# E203 register map
Vendor: Sipeed; Series: HBird Lichee tang
E203 CPU Coreplex, high-performance, 32-bit RV32IMAC core
CPU: E203, little endian
Registers are 32-bit, read-write, reset 0x0 unless marked. A register's access mark holds for its fields unless they carry their own. Offsets are from the block's base; lines under a group give offsets from that group; [hi:lo] are bit positions; {n}, {i} and the like mark numbered series; 'fields as' and 'values as' point back to an identical list; <NAME> marks a mode.

## Memory map
0x02000000 CLINT size 0x10000 — Core Local Interruptor.
0x0C000000 PLIC size 0x200008 — Platform-Level Interrupt Controller.
0x10000000 WDT size 0x40 — Watchdog Timer.
0x10000040 RTC size 0x30 — Real-Time Clock.
0x10000070 AON size 0x10 — AON Clock Configuration.
0x10000080 BACKUP size 0x80 — Backup Registers.
0x10000100 PMU size 0x50 — Power Management Unit.
0x10012000 GPIO0 size 0x1000 — General purpose input/output controller.
0x10013000 UART0 size 0x1000 — Universal Asynchronous Receiver/Transmitter.
0x10014000 QSPI0 size 0x1000 — Serial Peripheral Interface.
0x10015000 PWM0 size 0x1000 — Pulse-Width Modulation.
0x10023000 UART1 size 0x1000 — Universal Asynchronous Receiver/Transmitter.
0x10024000 QSPI1 size 0x1000 — Serial Peripheral Interface.
0x10025000 PWM1 size 0x1000
0x10034000 QSPI2 size 0x1000 — Serial Peripheral Interface.
0x10035000 PWM2 size 0x1000

## Interrupts
1 Watchdog_IRQ (WDT)
2 RTC_IRQ (RTC)
3 UART0_IRQ (UART0)
4 UART1_IRQ (UART1)
5 QSPI0_IRQ (QSPI0)
6 QSPI1_IRQ (QSPI1)
7 QSPI2_IRQ (QSPI2)
{n+8} GPIO_{n}_IRQ (GPIO0) (n=0..12)
21 GPIO_12_IRQ (GPIO0)
22 GPIO_14_IRQ (GPIO0)
23 GPIO_14_IRQ (GPIO0)
{n+8} GPIO_{n}_IRQ (GPIO0) (n=16..28)
37 GPIO_28_IRQ (GPIO0)
38 GPIO_30_IRQ (GPIO0)
39 GPIO_31_IRQ (GPIO0)
40 PWMO_CMP0_IRQ (PWM0)
41 PWMO_CMP1_IRQ (PWM0)
42 PWMO_CMP2_IRQ (PWM0)
43 PWMO_CMP3_IRQ (PWM0)
44 PWM1_CMP0_IRQ (PWM1)
45 PWM1_CMP1_IRQ (PWM1)
46 PWM1_CMP2_IRQ (PWM1)
47 PWM1_CMP3_IRQ (PWM1)
48 PWM2_CMP0_IRQ (PWM2)
49 PWM2_CMP1_IRQ (PWM2)
50 PWM2_CMP2_IRQ (PWM2)
51 PWM2_CMP3_IRQ (PWM2)

## PLIC — Platform-Level Interrupt Controller.
Base 0x0C000000
{0x0+4i} PRIORITY[{i}] (i=0..51) — PLIC Interrupt Priority Register.
  [2:0] PRIORITY
0x1000 PENDING_1 — PLIC Interrupt Pending Register 1.
0x1004 PENDING_2 — PLIC Interrupt Pending Register 2.
0x2000 ENABLE_1 — PLIC Interrupt Enable Register 1.
0x2004 ENABLE_2 — PLIC Interrupt Enable Register 2.
0x200000 THRESHOLD — PLIC Interrupt Priority Threshold Register.
  [2:0] THRESHOLD
0x200004 CLAIM — PLIC Claim/Complete Register.

## CLINT — Core Local Interruptor.
Base 0x02000000
0x00 MSIP — Machine Software Interrupt Pending Register.
0x4000 MTIMECMP_LO — Machine Timer Compare Register Low.
0x4004 MTIMECMP_HI — Machine Timer Compare Register High.
0xBFF8 MTIME_LO — Machine Timer Register Low.
0xBFFC MTIME_HI — Machine Timer Register High.

## GPIO0 — General purpose input/output controller.
Base 0x10012000
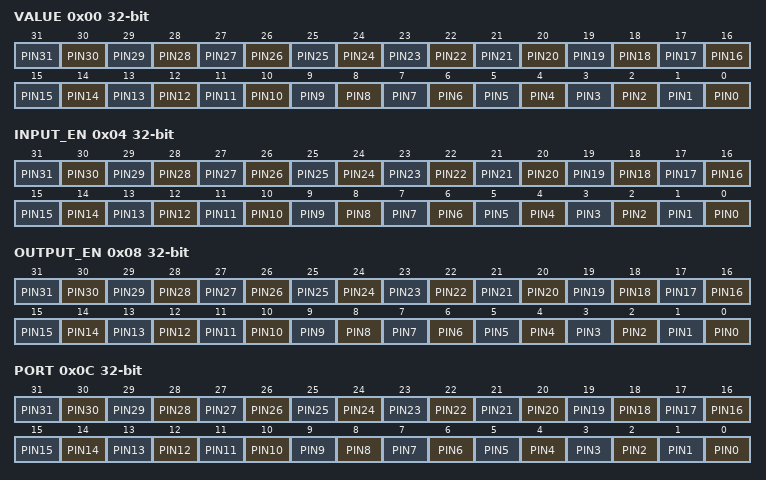
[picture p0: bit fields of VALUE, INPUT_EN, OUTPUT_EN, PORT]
0x00 VALUE — Pin value.
  [n] PIN{n} (n=0..31)
0x04 INPUT_EN — Pin input enable.
  [n] PIN{n} (n=0..31)
0x08 OUTPUT_EN — Pin output enable.
  [n] PIN{n} (n=0..31)
0x0C PORT — Output port value.
  [n] PIN{n} (n=0..31)
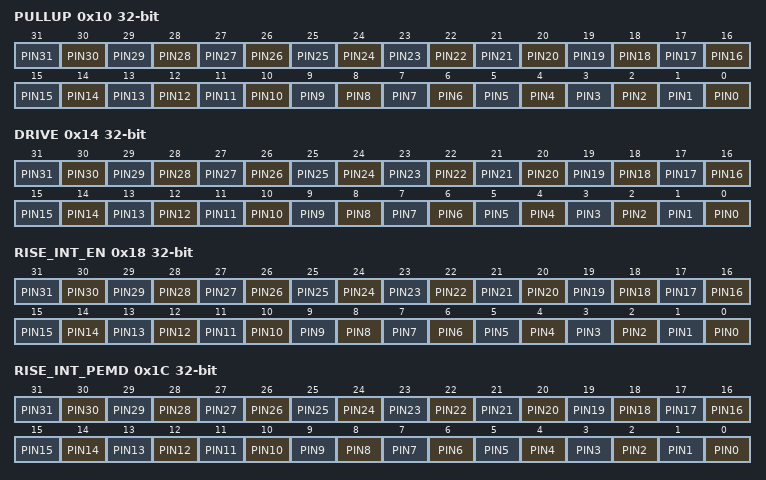
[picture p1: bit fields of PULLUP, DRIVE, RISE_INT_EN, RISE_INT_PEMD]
0x10 PULLUP — Internal Pull-Up enable.
  [n] PIN{n} (n=0..31)
0x14 DRIVE — Drive Strength.
  [n] PIN{n} (n=0..31)
0x18 RISE_INT_EN — Rise interrupt enable.
  [n] PIN{n} (n=0..31)
0x1C RISE_INT_PEMD — Rise interrupt pending.
  [n] PIN{n} (n=0..31)
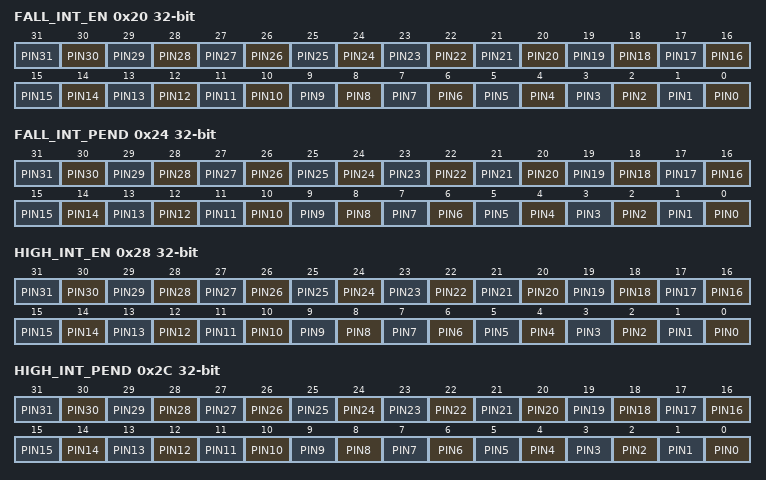
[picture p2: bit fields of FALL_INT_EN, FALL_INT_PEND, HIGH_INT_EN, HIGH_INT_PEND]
0x20 FALL_INT_EN — Fall interrupt enable.
  [n] PIN{n} (n=0..31)
0x24 FALL_INT_PEND — Fall interrupt pending.
  [n] PIN{n} (n=0..31)
0x28 HIGH_INT_EN — High interrupt enable.
  [n] PIN{n} (n=0..31)
0x2C HIGH_INT_PEND — High interrupt pending.
  [n] PIN{n} (n=0..31)
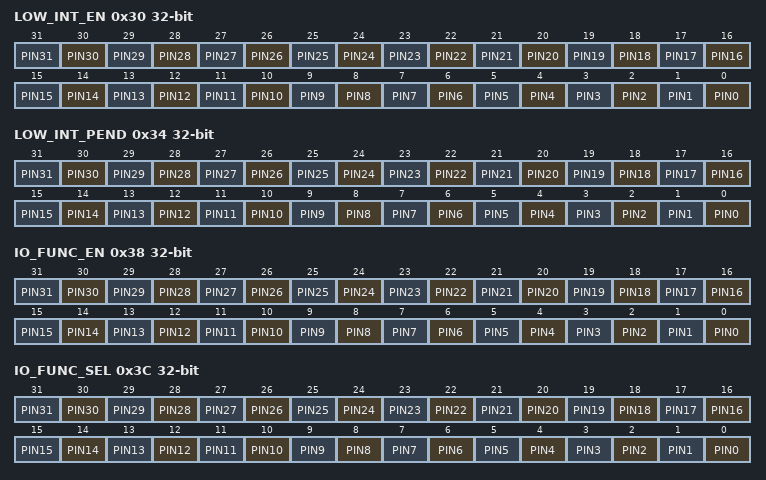
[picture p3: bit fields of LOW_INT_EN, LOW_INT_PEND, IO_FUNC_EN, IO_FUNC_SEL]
0x30 LOW_INT_EN — Low interrupt enable.
  [n] PIN{n} (n=0..31)
0x34 LOW_INT_PEND — Low interrupt pending.
  [n] PIN{n} (n=0..31)
0x38 IO_FUNC_EN — HW I/O function enable.
  [n] PIN{n} (n=0..31)
0x3C IO_FUNC_SEL — HW I/O function select.
  [n] PIN{n} (n=0..31)
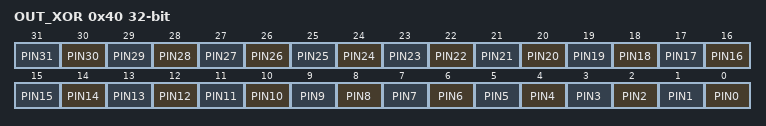
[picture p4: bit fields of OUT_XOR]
0x40 OUT_XOR — Output XOR (invert).
  [n] PIN{n} (n=0..31)
